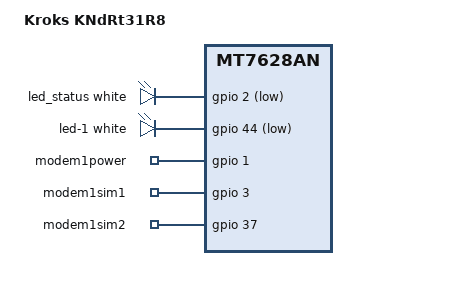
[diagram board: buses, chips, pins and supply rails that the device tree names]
#include "mt7628an_kroks_5eth.dtsi"
#include "mt7628an_kroks_poe.dtsi"

#include <dt-bindings/leds/common.h>

/ {
	compatible = "kroks,kndrt31r8", "mediatek,mt7628an-soc";
	model = "Kroks KNdRt31R8";

	aliases {
		led-boot = &led_status;
		led-failsafe = &led_status;
		led-running = &led_status;
		led-upgrade = &led_status;
	};

	leds {
		compatible = "gpio-leds";

		led_status: led-0 {
			function = LED_FUNCTION_STATUS;
			color = <LED_COLOR_ID_WHITE>;
			gpios = <&gpio 2 GPIO_ACTIVE_LOW>;
		};

		led-1 {
			function = LED_FUNCTION_WLAN;
			color = <LED_COLOR_ID_WHITE>;
			gpios = <&gpio 44 GPIO_ACTIVE_LOW>;
			linux,default-trigger = "phy0tpt";
		};
	};

	gpio_export {
		compatible = "gpio-export";
		#size-cells = <0>;

		modem1power {
			gpio-export,name = "modem1power";
			gpio-export,output = <1>;
			gpios = <&gpio 1 GPIO_ACTIVE_HIGH>;
		};

		modem1sim1 {
			gpio-export,name = "modem1sim1";
			gpio-export,output = <1>;
			gpios = <&gpio 3 GPIO_ACTIVE_HIGH>;
		};

		modem1sim2 {
			gpio-export,name = "modem1sim2";
			gpio-export,output = <0>;
			gpios = <&gpio 37 GPIO_ACTIVE_HIGH>;
		};
	};
};

&state_default {
	gpio {
		groups = "i2s", "refclk", "wled_an";
		function = "gpio";
	};
};
